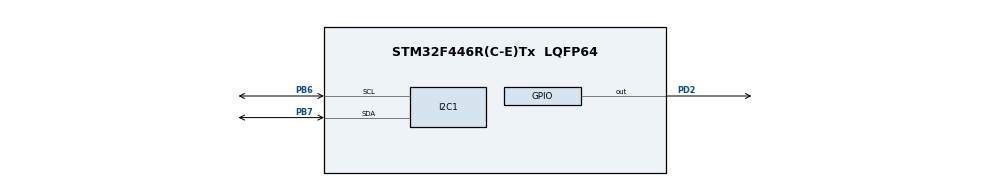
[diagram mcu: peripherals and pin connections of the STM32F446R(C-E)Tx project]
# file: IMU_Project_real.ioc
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Mcu.Family=STM32F4
Mcu.Name=STM32F446R(C-E)Tx
Mcu.Package=LQFP64
NVIC.PriorityGroup=NVIC_PRIORITYGROUP_4
PA13.Mode=Serial_Wire
PA13.Signal=SYS_JTMS-SWDIO
PA14.Mode=Serial_Wire
PA14.Signal=SYS_JTCK-SWCLK
PB6.Mode=I2C
PB6.Signal=I2C1_SCL
PB7.Mode=I2C
PB7.Signal=I2C1_SDA
PD2.Signal=GPIO_Output
PH0-OSC_IN.Mode=HSE-External-Oscillator
PH0-OSC_IN.Signal=RCC_OSC_IN
PH1-OSC_OUT.Mode=HSE-External-Oscillator
PH1-OSC_OUT.Signal=RCC_OSC_OUT
ProjectManager.HeapSize=0x200
ProjectManager.StackSize=0x400
ProjectManager.TargetToolchain=STM32CubeIDE
RCC.AHBFreq_Value=180000000
RCC.APB1CLKDivider=RCC_HCLK_DIV4
RCC.APB1Freq_Value=45000000
RCC.APB1TimFreq_Value=90000000
RCC.APB2CLKDivider=RCC_HCLK_DIV2
RCC.APB2Freq_Value=90000000
RCC.APB2TimFreq_Value=180000000
RCC.CortexFreq_Value=180000000
RCC.HCLKFreq_Value=180000000
RCC.HSE_VALUE=16000000
RCC.PLLM=8
RCC.PLLN=180
RCC.PLLSourceVirtual=RCC_PLLSOURCE_HSE
RCC.SYSCLKFreq_VALUE=180000000
RCC.SYSCLKSource=RCC_SYSCLKSOURCE_PLLCLK
RCC.USBFreq_Value=180000000
RCC.VCOOutputFreq_Value=360000000
board=custom

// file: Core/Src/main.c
/* USER CODE BEGIN Header */
/**
  ******************************************************************************
  * @file           : main.c
  * @brief          : Main program body
  ******************************************************************************
  * @attention
  *
  * Copyright (c) 2024 STMicroelectronics.
  * All rights reserved.
  *
  * This software is licensed under terms that can be found in the LICENSE file
  * in the root directory of this software component.
  * If no LICENSE file comes with this software, it is provided AS-IS.
  *
  ******************************************************************************
  */
/* USER CODE END Header */
#include "main.h"
#include "i2c.h"
#include "gpio.h"

/* USER CODE BEGIN PD */
#define MPU6050_ADDR 0xD0
#define MPU6050_SMPLRT_DIV_REG 0x19
#define MPU6050_CONFIG_REG 0x1A
#define MPU6050_GYRO_CONFIG_REG 0x1B
#define MPU6050_ACCEL_CONFIG_REG 0x1C
#define MPU6050_WHO_AM_I_REG 0x75
#define MPU6050_PWR_MGMT_1_REG 0x6B
#define MPU6050_ACCEL_XOUT_H_REG 0x3B
#define MPU6050_GYRO_XOUT_H_REG 0x43
/* USER CODE END PD */

/* USER CODE BEGIN PV */
uint8_t check;
int16_t Accel_X_RAW = 0;
int16_t Accel_Y_RAW = 0;
int16_t Accel_Z_RAW = 0;
int16_t Gyro_X_RAW = 0;
int16_t Gyro_Y_RAW = 0;
int16_t Gyro_Z_RAW = 0;

float Ax, Ay, Az, Gx, Gy, Gz;
/* USER CODE END PV */

void SystemClock_Config(void);
/* USER CODE BEGIN PFP */
void MPU6050_Init(void);
void MPU6050_Read_Accel(void);
void MPU6050_Read_Gyro(void);

void SystemClock_Config(void);
void Error_Handler(void);

/* USER CODE END PFP */

/* USER CODE BEGIN 0 */
void MPU6050_Init(void)
{
  uint8_t check;
  uint8_t Data;

  // check device ID WHO_AM_I
  HAL_I2C_Mem_Read(&hi2c1, MPU6050_ADDR, MPU6050_WHO_AM_I_REG, 1, &check, 1, 1000);

  if (check == 104)  // 0x68 will be returned by the sensor if everything goes well
  {
    // power management register 0X6B we should write all 0's to wake the sensor up
    Data = 0;
    HAL_I2C_Mem_Write(&hi2c1, MPU6050_ADDR, MPU6050_PWR_MGMT_1_REG, 1, &Data, 1, 1000);

    // Set DATA RATE of 1KHz by writing SMPLRT_DIV register
    Data = 0x07;
    HAL_I2C_Mem_Write(&hi2c1, MPU6050_ADDR, MPU6050_SMPLRT_DIV_REG, 1, &Data, 1, 1000);

    // Set accelerometer configuration in ACCEL_CONFIG Register
    // XA_ST=0,YA_ST=0,ZA_ST=0, FS_SEL=0 -> ± 2g
    Data = 0x00;
    HAL_I2C_Mem_Write(&hi2c1, MPU6050_ADDR, MPU6050_ACCEL_CONFIG_REG, 1, &Data, 1, 1000);

    // Set Gyroscopic configuration in GYRO_CONFIG Register
    // XG_ST=0,YG_ST=0,ZG_ST=0, FS_SEL=0 -> ± 250 °/s
    Data = 0x00;
    HAL_I2C_Mem_Write(&hi2c1, MPU6050_ADDR, MPU6050_GYRO_CONFIG_REG, 1, &Data, 1, 1000);
  }
}

void MPU6050_Read_Accel(void)
{
  uint8_t Rec_Data[6];

  // Read 6 BYTES of data starting from ACCEL_XOUT_H register
  HAL_I2C_Mem_Read(&hi2c1, MPU6050_ADDR, MPU6050_ACCEL_XOUT_H_REG, 1, Rec_Data, 6, 1000);

  Accel_X_RAW = (int16_t)(Rec_Data[0] << 8 | Rec_Data[1]);
  Accel_Y_RAW = (int16_t)(Rec_Data[2] << 8 | Rec_Data[3]);
  Accel_Z_RAW = (int16_t)(Rec_Data[4] << 8 | Rec_Data[5]);

  Ax = Accel_X_RAW / 16384.0;
  Ay = Accel_Y_RAW / 16384.0;
  Az = Accel_Z_RAW / 16384.0;
}

void MPU6050_Read_Gyro(void)
{
  uint8_t Rec_Data[6];

  // Read 6 BYTES of data starting from GYRO_XOUT_H register
  HAL_I2C_Mem_Read(&hi2c1, MPU6050_ADDR, MPU6050_GYRO_XOUT_H_REG, 1, Rec_Data, 6, 1000);

  Gyro_X_RAW = (int16_t)(Rec_Data[0] << 8 | Rec_Data[1]);
  Gyro_Y_RAW = (int16_t)(Rec_Data[2] << 8 | Rec_Data[3]);
  Gyro_Z_RAW = (int16_t)(Rec_Data[4] << 8 | Rec_Data[5]);

  Gx = Gyro_X_RAW / 131.0;
  Gy = Gyro_Y_RAW / 131.0;
  Gz = Gyro_Z_RAW / 131.0;
}
/* USER CODE END 0 */

int main(void)
{

  /* MCU Configuration--------------------------------------------------------*/

  /* Reset of all peripherals, Initializes the Flash interface and the Systick. */
  HAL_Init();

  /* Configure the system clock */
  SystemClock_Config();

  /* Initialize all configured peripherals */
  MX_GPIO_Init();
  MX_I2C1_Init();
  /* USER CODE BEGIN 2 */
  MPU6050_Init();  // Initialize MPU6050
  /* USER CODE END 2 */

  /* Infinite loop */
  while (1)
  {

    /* USER CODE BEGIN 3 */
    MPU6050_Read_Accel();  // Read accelerometer data
    MPU6050_Read_Gyro();   // Read gyroscope data

    // Here you can use Ax, Ay, Az, Gx, Gy, Gz values
    // For example: Send data via UART, control LEDs, etc.

    HAL_Delay(100);  // Wait for 100ms
  }
  /* USER CODE END 3 */
}
void Error_Handler(void)
{
  __disable_irq();
  while (1)
  {
  }
}
void SystemClock_Config(void)
{
  /* USER CODE BEGIN SystemClock_Config */
  /* System clock configuration code goes here */
  /* Please refer to your specific STM32F4 datasheet for proper configuration */
  /* USER CODE END SystemClock_Config */
}

/* Rest of the code remains unchanged */
